VERSION ""

NS_ :

BS_:

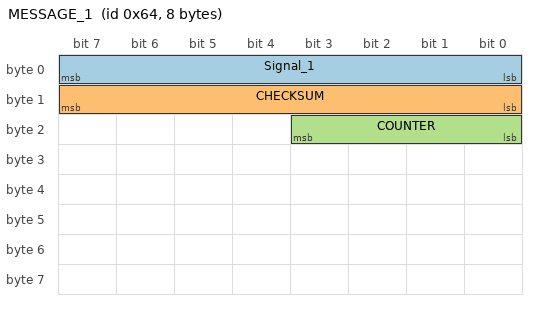
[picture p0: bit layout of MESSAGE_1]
BO_ 100 MESSAGE_1: 8 Vector__XXX
 SG_ Signal_1 : 0|8@1+ (1,0) [0|255] "" Vector__XXX
 SG_ CHECKSUM : 8|8@1+ (1,0) [0|255] "" Vector__XXX
 SG_ COUNTER : 16|4@1+ (1,0) [0|15] "" Vector__XXX
